# STM32U5A5 register map
File version: 1.8
CPU: CM33 r0p1, little endian, MPU, FPU, 4 interrupt priority bits
Registers are 32-bit, read-write, reset 0x0 unless marked. A register's access mark holds for its fields unless they carry their own. Offsets are from the block's base; [hi:lo] are bit positions; {n}, {i} and the like mark numbered series; 'fields as' and 'values as' point back to an identical list.

## RCC (part 2 of 2) — Reset and clock control
Base 0x46020C00
Same registers: SEC_RCC 0x56020C00
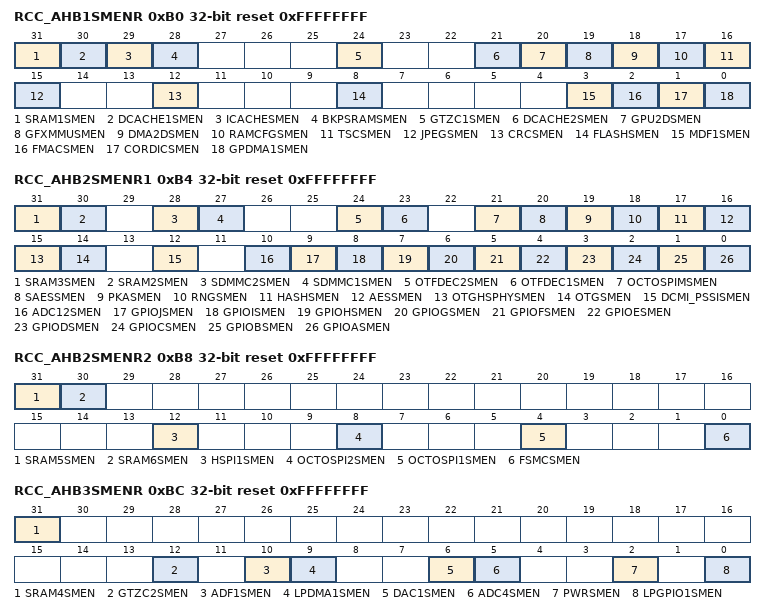
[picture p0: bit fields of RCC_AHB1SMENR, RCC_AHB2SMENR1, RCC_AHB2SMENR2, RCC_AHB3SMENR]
0xB0 RCC_AHB1SMENR reset 0xFFFFFFFF — RCC AHB1 peripheral clock enable in Sleep and Stop modes register
  [31] SRAM1SMEN — SRAM1 clock enable during Sleep and Stop modes
    0=SRAM1 clocks disabled by the clock gating during Sleep and Stop modes; 1=SRAM1 clocks enabled by the clock gating during Sleep and Stop modes
  [30] DCACHE1SMEN — DCACHE1 clock enable during Sleep and Stop modes
    0=DCACHE1 clocks disabled by the clock gating during Sleep and Stop modes; 1=DCACHE1 clocks enabled by the clock gating during Sleep and Stop modes
  [29] ICACHESMEN — ICACHE clock enable during Sleep and Stop modes
    0=ICACHE clocks disabled by the clock gating during Sleep and Stop modes; 1=ICACHE clocks enabled by the clock gating during Sleep and Stop modes
  [28] BKPSRAMSMEN — BKPSRAM clock enable during Sleep and Stop modes
    0=BKPSRAM clocks disabled by the clock gating during Sleep and Stop modes; 1=BKPSRAM clocks enabled by the clock gating during Sleep and Stop modes
  [24] GTZC1SMEN — GTZC1 clock enable during Sleep and Stop modes
    0=GTZC1 clocks disabled by the clock gating during Sleep and Stop modes; 1=GTZC1 clocks enabled by the clock gating during Sleep and Stop modes
  [21] DCACHE2SMEN — DCACHE2 clock enable during Sleep and Stop modes
    0=DCACHE2 clocks disabled by the clock gating during Sleep and Stop modes; 1=DCACHE2 clocks enabled by the clock gating during Sleep and Stop modes
  [20] GPU2DSMEN — GPU2D clock enable during Sleep and Stop modes
    0=GPU2D clocks disabled by the clock gating during Sleep and Stop modes; 1=GPU2D clocks enabled by the clock gating during Sleep and Stop modes
  [19] GFXMMUSMEN — GFXMMU clock enable during Sleep and Stop modes
    0=GFXMMU clocks disabled by the clock gating during Sleep and Stop modes; 1=GFXMMU clocks enabled by the clock gating during Sleep and Stop modes
  [18] DMA2DSMEN — DMA2D clock enable during Sleep and Stop modes
    0=DMA2D clocks disabled by the clock gating during Sleep and Stop modes; 1=DMA2D clocks enabled by the clock gating during Sleep and Stop modes
  [17] RAMCFGSMEN — RAMCFG clock enable during Sleep and Stop modes
    0=RAMCFG clocks disabled by the clock gating during Sleep and Stop modes; 1=RAMCFG clocks enabled by the clock gating during Sleep and Stop modes
  [16] TSCSMEN — TSC clocks enable during Sleep and Stop modes
    0=TSC clocks disabled by the clock gating during Sleep and Stop modes; 1=TSC clocks enabled by the clock gating during Sleep and Stop modes
  [15] JPEGSMEN — JPEG clocks enable during Sleep and Stop modes
    0=JPEG clocks disabled by the clock gating during Sleep and Stop modes; 1=JPEG clocks enabled by the clock gating during Sleep and Stop modes
  [12] CRCSMEN — CRC clocks enable during Sleep and Stop modes
    0=CRC clocks disabled by the clock gating during Sleep and Stop modes; 1=CRC clocks enabled by the clock gating during Sleep and Stop modes
  [8] FLASHSMEN — FLASH clocks enable during Sleep and Stop modes
    0=FLASH clocks disabled by the clock gating during Sleep and Stop modes; 1=FLASH clocks enabled by the clock gating during Sleep and Stop modes
  [3] MDF1SMEN — MDF1 clocks enable during Sleep and Stop modes.
    0=MDF1 clocks disabled by the clock gating during Sleep and Stop modes; 1=MDF1 clocks enabled by the clock gating during Sleep and Stop modes
  [2] FMACSMEN — FMAC clocks enable during Sleep and Stop modes.
    0=FMAC clocks disabled by the clock gating during Sleep and Stop modes; 1=FMAC clocks enabled by the clock gating during Sleep and Stop modes
  [1] CORDICSMEN — CORDIC clocks enable during Sleep and Stop modes
    0=CORDIC clocks disabled by the clock gating during Sleep and Stop modes; 1=CORDIC clocks enabled by the clock gating during Sleep and Stop modes
  [0] GPDMA1SMEN — GPDMA1 clocks enable during Sleep and Stop modes
    0=GPDMA1 clocks disabled by the clock gating during Sleep and Stop modes; 1=GPDMA1 clocks enabled by the clock gating during Sleep and Stop modes
0xB4 RCC_AHB2SMENR1 reset 0xFFFFFFFF — RCC AHB2 peripheral clock enable in Sleep and Stop modes register 1
  [31] SRAM3SMEN — SRAM3 clock enable during Sleep and Stop modes
    0=SRAM3 clocks disabled by the clock gating during Sleep and Stop modes; 1=SRAM3 clocks enabled by the clock gating during Sleep and Stop modes
  [30] SRAM2SMEN — SRAM2 clock enable during Sleep and Stop modes
    0=SRAM2 clocks disabled by the clock gating during Sleep and Stop modes; 1=SRAM2 clocks enabled by the clock gating during Sleep and Stop modes
  [28] SDMMC2SMEN — SDMMC2 clock enable during Sleep and Stop modes
    0=SDMMC2 clocks disabled by the clock gating during Sleep and Stop modes; 1=SDMMC2 clocks enabled by the clock gating during Sleep and Stop modes
  [27] SDMMC1SMEN — SDMMC1 clock enable during Sleep and Stop modes
    0=SDMMC1 clocks disabled by the clock gating during Sleep and Stop modes; 1=SDMMC1 clocks enabled by the clock gating during Sleep and Stop modes
  [24] OTFDEC2SMEN — OTFDEC2 clock enable during Sleep and Stop modes
    0=OTFDEC2 clocks disabled by the clock gating during Sleep and Stop modes; 1=OTFDEC2 clocks enabled by the clock gating during Sleep and Stop modes
  [23] OTFDEC1SMEN — OTFDEC1 clock enable during Sleep and Stop modes
    0=OTFDEC1 clocks disabled by the clock gating during Sleep and Stop modes; 1=OTFDEC1 clocks enabled by the clock gating during Sleep and Stop modes
  [21] OCTOSPIMSMEN — OCTOSPIM clock enable during Sleep and Stop modes
    0=OCTOSPIM clocks disabled by the clock gating during Sleep and Stop modes; 1=OCTOSPIM clocks enabled by the clock gating during Sleep and Stop modes
  [20] SAESSMEN — SAES accelerator clock enable during Sleep and Stop modes
    0=SAES clocks disabled by the clock gating during Sleep and Stop modes; 1=SAES clocks enabled by the clock gating during Sleep and Stop modes
  [19] PKASMEN — PKA clock enable during Sleep and Stop modes
    0=PKA clocks disabled by the clock gating during Sleep and Stop modes; 1=PKA clocks enabled by the clock gating during Sleep and Stop modes
  [18] RNGSMEN — RNG clock enable during Sleep and Stop modes
    0=RNG clocks disabled by the clock gating during Sleep and Stop modes; 1=RNG clocks enabled by the clock gating during Sleep and Stop modes
  [17] HASHSMEN — HASH clock enable during Sleep and Stop modes
    0=HASH clocks disabled by the clock gating during Sleep and Stop modes; 1=HASH clocks enabled by the clock gating during Sleep and Stop modes
  [16] AESSMEN — AES clock enable during Sleep and Stop modes
    0=AES clocks disabled by the clock gating during Sleep and Stop modes; 1=AES clocks enabled by the clock gating during Sleep and Stop modes
  [15] OTGHSPHYSMEN — OTG_HS PHY clock enable during Sleep and Stop modes
    0=OTG_HS PHY clocks disabled by the clock gating during Sleep and Stop modes; 1=OTG_HS PHY clocks enabled by the clock gating during Sleep and Stop modes
  [14] OTGSMEN — OTG_FS and OTG_HS clocks enable during Sleep and Stop modes
    0=OTG_FS and OTG_HS clocks disabled by the clock gating during Sleep and Stop modes; 1=OTG_FS and OTG_HS clocks enabled by the clock gating during Sleep and Stop modes
  [12] DCMI_PSSISMEN — DCMI and PSSI clock enable during Sleep and Stop modes
    0=DCMI and PSSI clocks disabled by the clock gating during Sleep and Stop modes; 1=DCMI and PSSI clocks enabled by the clock gating during Sleep and Stop modes
  [10] ADC12SMEN — ADC1 and ADC2 clock enable during Sleep and Stop modes
    0=ADC1 and ADC2 clocks disabled by the clock gating during Sleep and Stop modes; 1=ADC1 and ADC2 clocks enabled by the clock gating during Sleep and Stop modes
  [9] GPIOJSMEN — I/O port J clock enable during Sleep and Stop modes
    0=I/O port J clocks disabled by the clock gating during Sleep and Stop modes; 1=I/O port J clocks enabled by the clock gating during Sleep and Stop modes
  [8] GPIOISMEN — I/O port I clocks enable during Sleep and Stop modes
    0=I/O port I clocks disabled by the clock gating during Sleep and Stop modes; 1=I/O port I clocks enabled by the clock gating during Sleep and Stop modes
  [7] GPIOHSMEN — I/O port H clocks enable during Sleep and Stop modes
    0=I/O port H clocks disabled by the clock gating during Sleep and Stop modes; 1=I/O port H clocks enabled by the clock gating during Sleep and Stop modes
  [6] GPIOGSMEN — I/O port G clocks enable during Sleep and Stop modes
    0=I/O port G clocks disabled by the clock gating during Sleep and Stop modes; 1=I/O port G clocks enabled by the clock gating during Sleep and Stop modes
  [5] GPIOFSMEN — I/O port F clocks enable during Sleep and Stop modes
    0=I/O port F clocks disabled by the clock gating during Sleep and Stop modes; 1=I/O port F clocks enabled by the clock gating during Sleep and Stop modes
  [4] GPIOESMEN — I/O port E clocks enable during Sleep and Stop modes
    0=I/O port E clocks disabled by the clock gating during Sleep and Stop modes; 1=I/O port E clocks enabled by the clock gating during Sleep and Stop modes
  [3] GPIODSMEN — I/O port D clocks enable during Sleep and Stop modes
    0=I/O port D clocks disabled by the clock gating during Sleep and Stop modes; 1=I/O port D clocks enabled by the clock gating during Sleep and Stop modes
  [2] GPIOCSMEN — I/O port C clocks enable during Sleep and Stop modes
    0=I/O port C clocks disabled by the clock gating during Sleep and Stop modes; 1=I/O port C clocks enabled by the clock gating during Sleep and Stop modes
  [1] GPIOBSMEN — I/O port B clocks enable during Sleep and Stop modes
    0=I/O port B clocks disabled by the clock gating during Sleep and Stop modes; 1=I/O port B clocks enabled by the clock gating during Sleep and Stop modes
  [0] GPIOASMEN — I/O port A clocks enable during Sleep and Stop modes
    0=I/O port A clocks disabled by the clock gating during Sleep and Stop modes; 1=I/O port A clocks enabled by the clock gating during Sleep and Stop modes
0xB8 RCC_AHB2SMENR2 reset 0xFFFFFFFF — RCC AHB2 peripheral clock enable in Sleep and Stop modes register 2
  [31] SRAM5SMEN — SRAM5 clock enable during Sleep and Stop modes
    0=SRAM5 clocks disabled by the clock gating during Sleep and Stop modes; 1=SRAM5 clocks enabled by the clock gating during Sleep and Stop modes
  [30] SRAM6SMEN — SRAM6 clock enable during Sleep and Stop modes
    0=SRAM6 clocks disabled by the clock gating during Sleep and Stop modes; 1=SRAM6 clocks enabled by the clock gating during Sleep and Stop modes
  [12] HSPI1SMEN — HSPI1 clock enable during Sleep and Stop modes
    0=HSPI1 clocks disabled by the clock gating during Sleep and Stop modes; 1=HSP1I clocks enabled by the clock gating during Sleep and Stop modes
  [8] OCTOSPI2SMEN — OCTOSPI2 clock enable during Sleep and Stop modes
    0=OCTOSPI2 clocks disabled by the clock gating during Sleep and Stop modes; 1=OCTOSPI2 clocks enabled by the clock gating during Sleep and Stop modes
  [4] OCTOSPI1SMEN — OCTOSPI1 clock enable during Sleep and Stop modes
    0=OCTOSPI1 clocks disabled by the clock gating during Sleep and Stop modes; 1=OCTOSPI1 clocks enabled by the clock gating during Sleep and Stop modes
  [0] FSMCSMEN — FSMC clock enable during Sleep and Stop modes
    0=FSMC clocks disabled by the clock gating during Sleep and Stop modes; 1=FSMC clocks enabled by the clock gating during Sleep and Stop modes
0xBC RCC_AHB3SMENR reset 0xFFFFFFFF — RCC AHB3 peripheral clock enable in Sleep and Stop modes register
  [31] SRAM4SMEN — SRAM4 clock enable during Sleep and Stop modes
    0=SRAM4 clocks disabled by the clock gating during Sleep and Stop modes; 1=SRAM4 clocks enabled by the clock gating during Sleep and Stop modes
  [12] GTZC2SMEN — GTZC2 clock enable during Sleep and Stop modes
    0=GTZC2 clock disabled by the clock gating during Sleep and Stop modes; 1=GTZC2 clock enabled by the clock gating during Sleep and Stop modes
  [10] ADF1SMEN — ADF1 clock enable during Sleep and Stop modes
    0=ADF1 clock disabled by the clock gating during Sleep and Stop modes; 1=ADF1 clock enabled by the clock gating during Sleep and Stop modes
  [9] LPDMA1SMEN — LPDMA1 clock enable during Sleep and Stop modes
    0=LPDMA1 clock disabled by the clock gating during Sleep and Stop modes; 1=LPDMA1 clock enabled by the clock gating during Sleep and Stop modes
  [6] DAC1SMEN — DAC1 clock enable during Sleep and Stop modes
    0=DAC1 clock disabled by the clock gating during Sleep and Stop modes; 1=DAC1 clock enabled by the clock gating during Sleep and Stop modes
  [5] ADC4SMEN — ADC4 clock enable during Sleep and Stop modes
    0=ADC4 clock disabled by the clock gating during Sleep and Stop modes; 1=ADC4 clock enabled by the clock gating during Sleep and Stop modes
  [2] PWRSMEN — PWR clock enable during Sleep and Stop modes
    0=PWR clock disabled by the clock gating during Sleep and Stop modes; 1=PWR clock enabled by the clock gating during Sleep and Stop modes
  [0] LPGPIO1SMEN — LPGPIO1 enable during Sleep and Stop modes
    0=LPGPIO1 clock disabled by the clock gating during Sleep and Stop modes; 1=LPGPIO1 clock enabled by the clock gating during Sleep and Stop modes
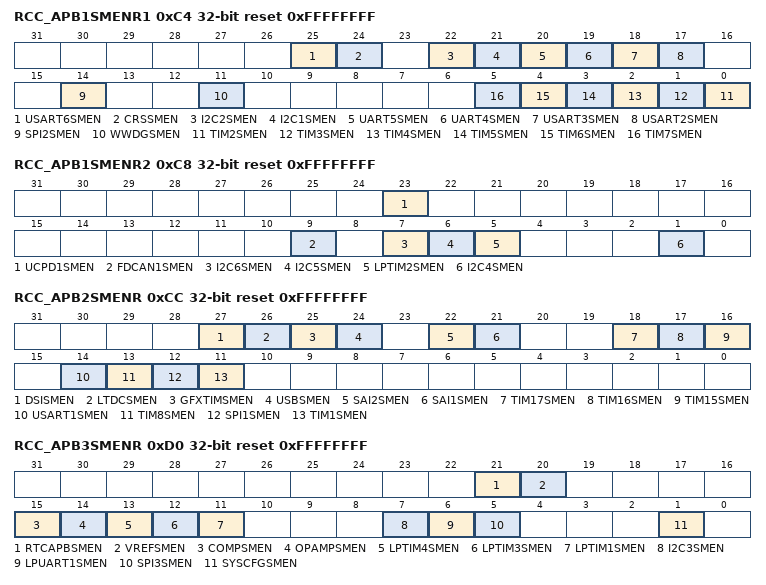
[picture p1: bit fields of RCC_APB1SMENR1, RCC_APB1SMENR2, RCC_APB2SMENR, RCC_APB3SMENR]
0xC4 RCC_APB1SMENR1 reset 0xFFFFFFFF — RCC APB1 peripheral clock enable in Sleep and Stop modes register 1
  [25] USART6SMEN — USART6 clock enable during Sleep and Stop modes
    0=USART6 clocks disabled by the clock gating during Sleep and Stop modes; 1=USART6 clocks enabled by the clock gating during Sleep and Stop modes
  [24] CRSSMEN — CRS clock enable during Sleep and Stop modes
    0=CRS clocks disabled by the clock gating during Sleep and Stop modes; 1=CRS clocks enabled by the clock gating during Sleep and Stop modes
  [22] I2C2SMEN — I2C2 clock enable during Sleep and Stop modes
    0=I2C2 clocks disabled by the clock gating during Sleep and Stop modes; 1=I2C2 clocks enabled by the clock gating during Sleep and Stop modes
  [21] I2C1SMEN — I2C1 clock enable during Sleep and Stop modes
    0=I2C1 clocks disabled by the clock gating during Sleep and Stop modes; 1=I2C1 clocks enabled by the clock gating during Sleep and Stop modes
  [20] UART5SMEN — UART5 clock enable during Sleep and Stop modes
    0=UART5 clocks disabled by the clock gating during Sleep and Stop modes; 1=UART5 clocks enabled by the clock gating during Sleep and Stop modes
  [19] UART4SMEN — UART4 clock enable during Sleep and Stop modes
    0=UART4 clocks disabled by the clock gating during Sleep and Stop modes; 1=UART4 clocks enabled by the clock gating during Sleep and Stop modes
  [18] USART3SMEN — USART3 clock enable during Sleep and Stop modes
    0=USART3 clocks disabled by the clock gating during Sleep and Stop modes; 1=USART3 clocks enabled by the clock gating during Sleep and Stop modes
  [17] USART2SMEN — USART2 clock enable during Sleep and Stop modes
    0=USART2 clocks disabled by the clock gating during Sleep and Stop modes; 1=USART2 clocks enabled by the clock gating during Sleep and Stop modes
  [14] SPI2SMEN — SPI2 clock enable during Sleep and Stop modes
    0=SPI2 clocks disabled by the clock gating during Sleep and Stop modes; 1=SPI2 clocks enabled by the clock gating during Sleep and Stop modes
  [11] WWDGSMEN — Window watchdog clock enable during Sleep and Stop modes
    0=Window watchdog clocks disabled by the clock gating during Sleep and Stop modes; 1=Window watchdog clocks enabled by the clock gating during Sleep and Stop modes
  [n-2] TIM{n}SMEN (n=2..7) — TIM{n} clock enable during Sleep and Stop modes
    0=TIM{n} clocks disabled by the clock gating during Sleep and Stop modes; 1=TIM{n} clocks enabled by the clock gating during Sleep and Stop modes
0xC8 RCC_APB1SMENR2 reset 0xFFFFFFFF — RCC APB1 peripheral clocks enable in Sleep and Stop modes register 2
  [23] UCPD1SMEN — UCPD1 clock enable during Sleep and Stop modes
    0=UCPD1 clocks disabled by the clock gating during Sleep and Stop modes; 1=UCPD1 clocks enabled by the clock gating during Sleep and Stop modes
  [9] FDCAN1SMEN — FDCAN1 clock enable during Sleep and Stop modes
    0=FDCAN1 clocks disabled by the clock gating during Sleep and Stop modes; 1=FDCAN1 clocks enabled by the clock gating during Sleep and Stop modes
  [7] I2C6SMEN — I2C6 clock enable during Sleep and Stop modes
    0=I2C6 clocks disabled by the clock gating during Sleep and Stop modes; 1=I2C6 clocks enabled by the clock gating during Sleep and Stop modes
  [6] I2C5SMEN — I2C5 clock enable during Sleep and Stop modes
    0=I2C5 clocks disabled by the clock gating during Sleep and Stop modes; 1=I2C5 clocks enabled by the clock gating during Sleep and Stop modes
  [5] LPTIM2SMEN — LPTIM2 clock enable during Sleep and Stop modes
    0=LPTIM2 clocks disabled by the clock gating during Sleep and Stop modes; 1=LPTIM2 clocks enabled by the clock gating during Sleep and Stop modes
  [1] I2C4SMEN — I2C4 clock enable during Sleep and Stop modes
    0=I2C4 clocks disabled by the clock gating during Sleep and Stop modes; 1=I2C4 clocks enabled by the clock gating during Sleep and Stop modes
0xCC RCC_APB2SMENR reset 0xFFFFFFFF — RCC APB2 peripheral clocks enable in Sleep and Stop modes register
  [27] DSISMEN — DSI clock enable during Sleep and Stop modes
    0=DSI clocks disabled by the clock gating during Sleep and Stop modes; 1=DSI clocks enabled by the clock gating during Sleep and Stop modes
  [26] LTDCSMEN — LTDC clock enable during Sleep and Stop modes
    0=LTDC clocks disabled by the clock gating during Sleep and Stop modes; 1=LTDC clocks enabled by the clock gating during Sleep and Stop modes
  [25] GFXTIMSMEN — GFXTIM clock enable during Sleep and Stop modes
    0=GFXTIM clocks disabled by the clock gating during Sleep and Stop modes; 1=GFXTIM clocks enabled by the clock gating during Sleep and Stop modes
  [24] USBSMEN — USB clock enable during Sleep and Stop modes
    0=USB clocks disabled by the clock gating during Sleep and Stop modes; 1=USB clocks enabled by the clock gating during Sleep and Stop modes
  [22] SAI2SMEN — SAI2 clock enable during Sleep and Stop modes
    0=SAI2 clocks disabled by the clock gating during Sleep and Stop modes; 1=SAI2 clocks enabled by the clock gating during Sleep and Stop modes
  [21] SAI1SMEN — SAI1 clock enable during Sleep and Stop modes
    0=SAI1 clocks disabled by the clock gating during Sleep and Stop modes; 1=SAI1 clocks enabled by the clock gating during Sleep and Stop modes
  [18] TIM17SMEN — TIM17 clock enable during Sleep and Stop modes
    0=TIM17 clocks disabled by the clock gating during Sleep and Stop modes; 1=TIM17 clocks enabled by the clock gating during Sleep and Stop modes
  [17] TIM16SMEN — TIM16 clock enable during Sleep and Stop modes
    0=TIM16 clocks disabled by the clock gating during Sleep and Stop modes; 1=TIM16 clocks enabled by the clock gating during Sleep and Stop modes
  [16] TIM15SMEN — TIM15 clock enable during Sleep and Stop modes
    0=TIM15 clocks disabled by the clock gating during Sleep and Stop modes; 1=TIM15 clocks enabled by the clock gating during Sleep and Stop modes
  [14] USART1SMEN — USART1 clock enable during Sleep and Stop modes
    0=USART1clocks disabled by the clock gating during Sleep and Stop modes; 1=USART1clocks enabled by the clock gating during Sleep and Stop modes
  [13] TIM8SMEN — TIM8 clock enable during Sleep and Stop modes
    0=TIM8 clocks disabled by the clock gating during Sleep and Stop modes; 1=TIM8 clocks enabled by the clock gating during Sleep and Stop modes
  [12] SPI1SMEN — SPI1 clock enable during Sleep and Stop modes
    0=SPI1 clocks disabled by the clock gating during Sleep and Stop modes; 1=SPI1 clocks enabled by the clock gating during Sleep and Stop modes
  [11] TIM1SMEN — TIM1 clock enable during Sleep and Stop modes
    0=TIM1 clocks disabled by the clock gating during Sleep and Stop modes; 1=TIM1 clocks enabled by the clock gating during Sleep and Stop modes
0xD0 RCC_APB3SMENR reset 0xFFFFFFFF — RCC APB3 peripheral clock enable in Sleep and Stop modes register
  [21] RTCAPBSMEN — RTC and TAMP APB clock enable during Sleep and Stop modes
    0=RTC and TAMP APB clock disabled by the clock gating during Sleep and Stop modes; 1=RTC and TAMP APB clock enabled by the clock gating during Sleep and Stop modes
  [20] VREFSMEN — VREFBUF clock enable during Sleep and Stop modes
    0=VREFBUF clocks disabled by the clock gating during Sleep and Stop modes; 1=VREFBUF clocks enabled by the clock gating during Sleep and Stop modes
  [15] COMPSMEN — COMP clock enable during Sleep and Stop modes
    0=COMP clocks disabled by the clock gating during Sleep and Stop modes; 1=COMP clocks enabled by the clock gating during Sleep and Stop modes
  [14] OPAMPSMEN — OPAMP clock enable during Sleep and Stop modes
    0=OPAMP clocks disabled by the clock gating during Sleep and Stop modes; 1=OPAMP clocks enabled by the clock gating during Sleep and Stop modes
  [13] LPTIM4SMEN — LPTIM4 clock enable during Sleep and Stop modes
    0=LPTIM4 clocks disabled by the clock gating during Sleep and Stop modes; 1=LPTIM4 clocks enabled by the clock gating during Sleep and Stop modes
  [12] LPTIM3SMEN — LPTIM3 clock enable during Sleep and Stop modes
    0=LPTIM3 clocks disabled by the clock gating during Sleep and Stop modes; 1=LPTIM3 clocks enabled by the clock gating during Sleep and Stop modes
  [11] LPTIM1SMEN — LPTIM1 clock enable during Sleep and Stop modes
    0=LPTIM1 clocks disabled by the clock gating during Sleep and Stop modes; 1=LPTIM1 clocks enabled by the clock gating during Sleep and Stop modes
  [7] I2C3SMEN — I2C3 clock enable during Sleep and Stop modes
    0=I2C3 clocks disabled by the clock gating during Sleep and Stop modes; 1=I2C3 clocks enabled by the clock gating during Sleep and Stop modes
  [6] LPUART1SMEN — LPUART1 clock enable during Sleep and Stop modes
    0=LPUART1 clocks disabled by the clock gating during Sleep and Stop modes; 1=LPUART1 clocks enabled by the clock gating during Sleep and Stop modes
  [5] SPI3SMEN — SPI3 clock enable during Sleep and Stop modes
    0=SPI3 clocks disabled by the clock gating during Sleep and Stop modes; 1=SPI3 clocks enabled by the clock gating during Sleep and Stop modes
  [1] SYSCFGSMEN — SYSCFG clock enable during Sleep and Stop modes
    0=SYSCFG clocks disabled by the clock gating during Sleep and Stop modes; 1=SYSCFG clocks enabled by the clock gating during Sleep and Stop modes
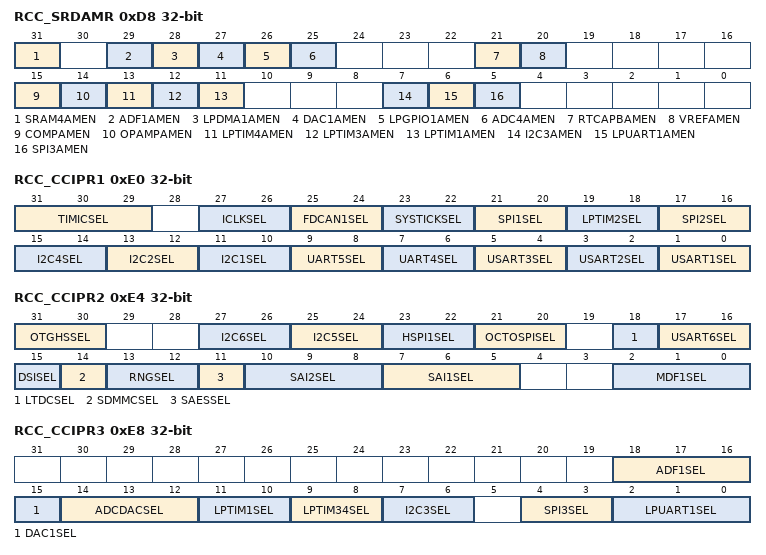
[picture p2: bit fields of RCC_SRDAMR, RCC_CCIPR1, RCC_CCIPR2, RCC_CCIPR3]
0xD8 RCC_SRDAMR — RCC SmartRun domain peripheral autonomous mode register
  [31] SRAM4AMEN — SRAM4 autonomous mode enable in Stop 0/1/2 mode
    0=SRAM4 autonomous mode disabled during Stop 0/1/2 mode; 1=SRAM4 autonomous mode enabled during Stop 0/1/2 mode
  [29] ADF1AMEN — ADF1 autonomous mode enable in Stop 0/1/2 mode
    0=ADF1 autonomous mode disabled during Stop 0/1/2 mode; 1=ADF1 autonomous mode enabled during Stop 0/1/2 mode
  [28] LPDMA1AMEN — LPDMA1 autonomous mode enable in Stop 0/1/2 mode
    0=LPDMA1 autonomous mode disabled during Stop 0/1/2 mode; 1=LPDMA1 autonomous mode enabled during Stop 0/1/2 mode
  [27] DAC1AMEN — DAC1 autonomous mode enable in Stop 0/1/2 mode
    0=DAC1 autonomous mode disabled during Stop 0/1/2 mode; 1=DAC1 autonomous mode enabled during Stop 0/1/2 mode
  [26] LPGPIO1AMEN — LPGPIO1 autonomous mode enable in Stop 0/1/2 mode
    0=LPGPIO1 autonomous mode disabled during Stop 0/1/2 mode; 1=LPGPIO1 autonomous mode enabled during Stop 0/1/2 mode
  [25] ADC4AMEN — ADC4 autonomous mode enable in Stop 0/1/2 mode
    0=ADC4 autonomous mode disabled during Stop 0/1/2 mode; 1=ADC4 autonomous mode enabled during Stop 0/1/2 mode
  [21] RTCAPBAMEN — RTC and TAMP autonomous mode enable in Stop 0/1/2 mode
    0=RTC and TAMP autonomous mode disabled during Stop 0/1/2mode; 1=RTC and TAMP autonomous mode enabled during Stop 0/1/2 mode
  [20] VREFAMEN — VREFBUF autonomous mode enable in Stop 0/1/2 mode
    0=VREFBUF autonomous mode disabled during Stop 0/1/2 mode; 1=VREFBUF autonomous mode enabled during Stop 0/1/2 mode
  [15] COMPAMEN — COMP autonomous mode enable in Stop 0/1/2 mode
    0=COMP autonomous mode disabled during Stop 0/1/2 mode; 1=COMP autonomous mode enabled during Stop 0/1/2 mode
  [14] OPAMPAMEN — OPAMP autonomous mode enable in Stop 0/1/2 mode
    0=OPAMP autonomous mode disabled during Stop 0/1/2 mode; 1=OPAMP autonomous mode enabled during Stop 0/1/2 mode
  [13] LPTIM4AMEN — LPTIM4 autonomous mode enable in Stop 0/1/2 mode
    0=LPTIM4 autonomous mode disabled during Stop 0/1/2 mode; 1=LPTIM4 autonomous mode enabled during Stop 0/1/2 mode
  [12] LPTIM3AMEN — LPTIM3 autonomous mode enable in Stop 0/1/2 mode
    0=LPTIM3 autonomous mode disabled during Stop 0/1/2 mode; 1=LPTIM3 autonomous mode enabled during Stop 0/1/2 mode
  [11] LPTIM1AMEN — LPTIM1 autonomous mode enable in Stop 0/1/2 mode
    0=LPTIM1 autonomous mode disabled during Stop 0/1/2 mode; 1=LPTIM1 autonomous mode enabled during Stop 0/1/2 mode
  [7] I2C3AMEN — I2C3 autonomous mode enable in Stop 0/1/2 mode
    0=I2C3 autonomous mode disabled during Stop 0/1/2 mode; 1=I2C3 autonomous mode enabled during Stop 0/1/2 mode
  [6] LPUART1AMEN — LPUART1 autonomous mode enable in Stop 0/1/2 mode
    0=LPUART1 autonomous mode disabled during Stop 0/1/2 mode; 1=LPUART1 autonomous mode enabled during Stop 0/1/2 mode
  [5] SPI3AMEN — SPI3 autonomous mode enable in Stop 0,1, 2 mode
    0=SPI3 autonomous mode disabled during Stop 0/1/2 mode; 1=SPI3 autonomous mode enabled during Stop 0/1/2 mode
0xE0 RCC_CCIPR1 — RCC peripherals independent clock configuration register 1
  [31:29] TIMICSEL — Clock sources for TIM16,TIM17, and LPTIM2 internal input capture
    4=HSI/256, MSIS/1024 and MSIS/4 generated and can be selected by TIM16, TIM17, and LPTIM2 as internal input capture; 5=HSI/256, MSIS/1024 and MSIK/4 generated and can be selected by TIM16, TIM17, and LPTIM2 as internal input capture; 6=HSI/256, MSIK/1024 and MSIS/4 generated and can be selected by TIM16, TIM17 ,and LPTIM2 as internal input capture; 7=HSI/256, MSIK/1024 and MSIK/4 generated and can be selected by TIM16, TIM17, and LPTIM2 as internal input capture
  [27:26] ICLKSEL — Intermediate clock source selection
    0=HSI48 clock selected; 1=PLL2 Q (pll2_q_ck) selected; 2=PLL1 Q (pll1_q_ck) selected; 3=MSIK clock selected
  [25:24] FDCAN1SEL — FDCAN1 kernel clock source selection
    0=HSE clock selected; 1=PLL1Q (pll1_q_ck) selected; 2=PLL2 P (pll2_p_ck) selected
  [23:22] SYSTICKSEL — SysTick clock source selection
    0=HCLK/8 selected; 1=LSI selected; 2=LSE selected
  [21:20] SPI1SEL — SPI1 kernel clock source selection
    0=PCLK2 selected; 1=SYSCLK selected; 2=HSI16 selected; 3=MSIK selected
  [19:18] LPTIM2SEL — Low-power timer 2 kernel clock source selection
    0=PCLK1 selected; 1=LSI selected; 2=HSI16 selected; 3=LSE selected
  [17:16] SPI2SEL — SPI2 kernel clock source selection
    0=PCLK1 selected; 1=SYSCLK selected; 2=HSI16 selected; 3=MSIK selected
  [15:14] I2C4SEL — I2C4 kernel clock source selection
    values as SPI2SEL
  [13:12] I2C2SEL — I2C2 kernel clock source selection
    values as SPI2SEL
  [11:10] I2C1SEL — I2C1 kernel clock source selection
    values as SPI2SEL
  [9:8] UART5SEL — UART5 kernel clock source selection
    0=PCLK1 selected; 1=SYSCLK selected; 2=HSI16 selected; 3=LSE selected
  [7:6] UART4SEL — UART4 kernel clock source selection
    values as UART5SEL
  [5:4] USART3SEL — USART3 kernel clock source selection
    values as UART5SEL
  [3:2] USART2SEL — USART2 kernel clock source selection
    values as UART5SEL
  [1:0] USART1SEL — USART1 kernel clock source selection
    0=PCLK2 selected; 1=SYSCLK selected; 2=HSI16 selected; 3=LSE selected
0xE4 RCC_CCIPR2 — RCC peripherals independent clock configuration register 2
  [31:30] OTGHSSEL — OTG_HS PHY kernel clock source selection
    0=HSE selected; 1=PLL1 P (pll1_q_ck) selected,; 2=HSE/2 selected; 3=PLL1 P divided by 2 (pll1_p_ck/2) selected
  [27:26] I2C6SEL — I2C6 kernel clock source selection
    values as RCC_CCIPR1.SPI2SEL
  [25:24] I2C5SEL — I2C5 kernel clock source selection
    values as RCC_CCIPR1.SPI2SEL
  [23:22] HSPI1SEL — HSPI1 kernel clock source selection
    0=SYSCLK selected; 1=PLL1 Q (pll1_q_ck) selected, can be up to 200 MHz; 2=PLL2 Q (pll2_q_ck) selected, can be up to 200 MHz; 3=PLL3 R (pll3_r_ck) selected, can be up to 200 MHz
  [21:20] OCTOSPISEL — OCTOSPI1 and OCTOSPI2 kernel clock source selection
    0=SYSCLK selected; 1=MSIK selected; 2=PLL1 Q (pll1_q_ck) selected, can be up to 200 MHz; 3=PLL2 Q (pll2_q_ck) selected, can be up to 200 MHz
  [18] LTDCSEL — LTDC kernel clock source selection
    0=PLL3 R (pll3_r_ck) selected; 1=PLL2 R (pll2_r_ck) selected
  [17:16] USART6SEL — USART6 kernel clock source selection
    values as RCC_CCIPR1.UART5SEL
  [15] DSISEL — DSI kernel clock source selection
    0=PLL3 P (pll3_p_ck) selected; 1=DSI PHY PLL output selected
  [14] SDMMCSEL — SDMMC1 and SDMMC2 kernel clock source selection
    0=ICLK clock selected; 1=PLL1 P (pll1_p_ck) selected, in case higher than 48MHz is needed (for SDR50 mode)
  [13:12] RNGSEL — RNG kernel clock source selection
    0=HSI48 selected; 1=HSI48 / 2 selected, can be used in range 4; 2=HSI16 selected
  [11] SAESSEL — SAES kernel clock source selection
    0=SHSI selected; 1=SHSI / 2 selected, can be used in range 4
  [10:8] SAI2SEL — SAI2 kernel clock source selection
    0=PLL2 P (pll2_p_ck) selected; 1=PLL3 P (pll3_p_ck) selected; 2=PLL1 P (pll1_p_ck) selected; 3=input pin AUDIOCLK selected; 4=HSI16 clock selected
  [7:5] SAI1SEL — SAI1 kernel clock source selection
    values as SAI2SEL
  [2:0] MDF1SEL — MDF1 kernel clock source selection
    0=HCLK selected; 1=PLL1 P (pll1_p_ck) selected; 2=PLL3 Q (pll3_q_ck) selected; 3=input pin AUDIOCLK selected; 4=MSIK clock selected
0xE8 RCC_CCIPR3 — RCC peripherals independent clock configuration register 3
  [18:16] ADF1SEL — ADF1 kernel clock source selection
    values as RCC_CCIPR2.MDF1SEL
  [15] DAC1SEL — DAC1 sample-and-hold clock source selection
    0=LSE selected; 1=LSI selected
  [14:12] ADCDACSEL — ADC1, ADC2, ADC4 and DAC1 kernel clock source selection
    0=HCLK clock selected; 1=SYSCLK selected; 2=PLL2 R (pll2_r_ck) selected; 3=HSE clock selected; 4=HSI16 clock selected; 5=MSIK clock selected
  [11:10] LPTIM1SEL — LPTIM1 kernel clock source selection
    0=MSIK clock selected; 1=LSI selected; 2=HSI16 selected; 3=LSE selected
  [9:8] LPTIM34SEL — LPTIM3 and LPTIM4 kernel clock source selection
    0=MSIK clock selected; 1=LSI selected; 2=HSI selected; 3=LSE selected
  [7:6] I2C3SEL — I2C3 kernel clock source selection
    0=PCLK3 selected; 1=SYSCLK selected; 2=HSI16 selected; 3=MSIK selected
  [4:3] SPI3SEL — SPI3 kernel clock source selection
    values as I2C3SEL
  [2:0] LPUART1SEL — LPUART1 kernel clock source selection
    0=PCLK3 selected; 1=SYSCLK selected; 2=HSI16 selected; 3=LSE selected; 4=MSIK selected
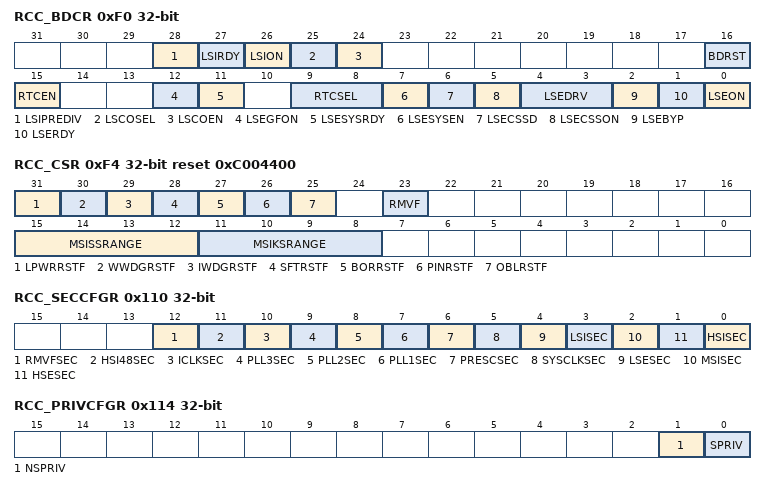
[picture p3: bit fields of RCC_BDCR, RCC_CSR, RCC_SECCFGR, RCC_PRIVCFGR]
0xF0 RCC_BDCR access per field — RCC backup domain control register
  [28] LSIPREDIV rw — Low-speed clock divider configuration
    0=LSI not divided; 1=LSI divided by 128
  [27] LSIRDY rw — LSI oscillator ready
    0=LSI oscillator not ready; 1=LSI oscillator ready
  [26] LSION rw — LSI oscillator enable
    0=LSI oscillator OFF; 1=LSI oscillator ON
  [25] LSCOSEL rw — Low-speed clock output selection
    0=LSI clock selected; 1=LSE clock selected
  [24] LSCOEN rw — Low-speed clock output (LSCO) enable
    0=LSCO disabled; 1=LSCO enabled
  [16] BDRST rw — Backup domain software reset
    0=Reset not activated; 1=Reset the entire backup domain
  [15] RTCEN rw — RTC and TAMP clock enable
    0=RTC and TAMP clock disabled; 1=RTC and TAMP clock enabled
  [12] LSEGFON rw — LSE clock glitch filter enable
    0=LSE glitch filter disabled; 1=LSE glitch filter enabled
  [11] LSESYSRDY ro — LSE system clock (LSESYS) ready
    0=LSESYS clock not ready; 1=LSESYS clock ready
  [9:8] RTCSEL rw — RTC and TAMP clock source selection
    0=No clock selected; 1=LSE oscillator clock selected; 2=LSI oscillator clock selected; 3=HSE oscillator clock divided by 32 selected
  [7] LSESYSEN rw — LSE system clock (LSESYS) enable
    0=LSE can be used only for RTC, TAMP, and CSS on LSE; 1=LSE can be used by any other peripheral or function
  [6] LSECSSD ro — CSS on LSE failure detection
    0=No failure detected on LSE; 1=Failure detected on LSE
  [5] LSECSSON rw — CSS on LSE enable
    0=CSS on LSE OFF; 1=CSS on LSE ON
  [4:3] LSEDRV rw — LSE oscillator drive capability
    0=Xtal mode' lower driving capability; 1=Xtal mode' medium-low driving capability; 2=Xtal mode' medium-high driving capability; 3=Xtal mode' higher driving capability
  [2] LSEBYP rw — LSE oscillator bypass
    0=LSE oscillator not bypassed; 1=LSE oscillator bypassed
  [1] LSERDY ro — LSE oscillator ready
    0=LSE oscillator not ready; 1=LSE oscillator ready
  [0] LSEON rw — LSE oscillator enable
    0=LSE oscillator off; 1=LSE oscillator on
0xF4 RCC_CSR access per field reset 0xC004400 — RCC control/status register
  [31] LPWRRSTF ro — Low-power reset flag
    0=No illegal low-power mode reset occurred; 1=Illegal low-power mode reset occurred
  [30] WWDGRSTF ro — Window watchdog reset flag
    0=No window watchdog reset occurred; 1=Window watchdog reset occurred
  [29] IWDGRSTF ro — Independent watchdog reset flag
    0=No independent watchdog reset occurred; 1=Independent watchdog reset occurred
  [28] SFTRSTF ro — Software reset flag
    0=No software reset occurred; 1=Software reset occurred
  [27] BORRSTF ro — Brownout reset or an exit from Shutdown mode reset flag
    0=No BOR/exit from Shutdown mode reset occurred; 1=BOR/exit from Shutdown mode reset occurred
  [26] PINRSTF ro — NRST pin reset flag
    0=No reset from NRST pin occurred; 1=Reset from NRST pin occurred
  [25] OBLRSTF ro — Option-byte loader reset flag
    0=No reset from option-byte loading occurred; 1=Reset from option-byte loading occurred
  [23] RMVF rw — Remove reset flag
    0=No effect; 1=Clear the reset flags
  [15:12] MSISSRANGE rw — MSIS range after Standby mode
    4=range 4 around 4M Hz (reset value); 5=range 5 around 2 MHz; 6=range 6 around 1.33 MHz; 7=range 7 around 1 MHz; 8=range 8 around 3.072 MHz
  [11:8] MSIKSRANGE rw — MSIK range after Standby mode
    values as MSISSRANGE
0x110 RCC_SECCFGR — RCC secure configuration register
  [all] fields
    0=non secure; 1=secure
  [12] RMVFSEC — Remove reset flag security
  [11] HSI48SEC — HSI48 clock configuration and status bit security
  [10] ICLKSEC — Intermediate clock source selection security
  [9] PLL3SEC — PLL3 clock configuration and status bit security
  [8] PLL2SEC — PLL2 clock configuration and status bit security
  [7] PLL1SEC — PLL1 clock configuration and status bit security
  [6] PRESCSEC — AHBx/APBx prescaler configuration bits security
  [5] SYSCLKSEC — SYSCLK clock selection, STOPWUCK bit, clock output on MCO configuration security
  [4] LSESEC — LSE clock configuration and status bit security
  [3] LSISEC — LSI clock configuration and status bit security
  [2] MSISEC — MSI clock configuration and status bit security
  [1] HSESEC — HSE clock configuration bits, status bit and HSE_CSS security
  [0] HSISEC — HSI clock configuration and status bit security
0x114 RCC_PRIVCFGR — RCC privilege configuration register
  [1] NSPRIV — RCC non-secure function privilege configuration
    0=Read and write to RCC non-secure functions can be done by privileged or unprivileged access; 1=Read and write to RCC non-secure functions can be done by privileged access only
  [0] SPRIV — RCC secure function privilege configuration
    0=Read and write to RCC secure functions can be done by privileged or unprivileged access; 1=Read and write to RCC secure functions can be done by privileged access only
